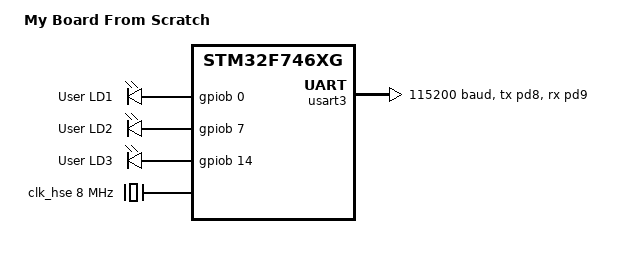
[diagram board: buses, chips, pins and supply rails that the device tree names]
/dts-v1/;
#include <st/f7/stm32f746Xg.dtsi>
#include <st/f7/stm32f746zgtx-pinctrl.dtsi>

/* Basic clock configuration required for this board to work,
** UART required for logging. */

/ {
    model = "My Board From Scratch";
    compatible = "bebelno,my_board";

    chosen {
        zephyr,console = &usart3;
        zephyr,sram = &sram0;
		zephyr,flash = &flash0;
		zephyr,dtcm = &dtcm;
    };

    aliases {
        led0 = &green_led;
		led1 = &blue_led;
		led2 = &red_led;
    };

    leds: leds {
		compatible = "gpio-leds";

		green_led: led_0 {
			gpios = <&gpiob 0 GPIO_ACTIVE_HIGH>;
			label = "User LD1";
		};

		blue_led: led_1 {
			gpios = <&gpiob 7 GPIO_ACTIVE_HIGH>;
			label = "User LD2";
		};

		red_led: led_2 {
			gpios = <&gpiob 14 GPIO_ACTIVE_HIGH>;
			label = "User LD3";
		};
	};
};

&usart3 {
	pinctrl-0 = <&usart3_tx_pd8 &usart3_rx_pd9>;
	pinctrl-names = "default";
	current-speed = <115200>;
	status = "okay";
};

&clk_hse {
	hse-bypass;
	clock-frequency = <DT_FREQ_M(8)>; /* STLink 8MHz clock */
	status = "okay";
};

&pll {
	div-m = <4>;
	mul-n = <192>;
	div-p = <2>;
	div-q = <8>;
	clocks = <&clk_hse>;
	status = "okay";
};

&rcc {
	clocks = <&pll>;
	clock-frequency = <DT_FREQ_M(192)>;
	ahb-prescaler = <1>;
	apb1-prescaler = <4>;
	apb2-prescaler = <2>;
};
